VERSION ""

NS_ :

BS_:

BU_: Connectivity CCU
VAL_TABLE_ vtbSensorReqCause 15 "SNA" 2 "by Request 2" 1 "by Request 1" 0 "normal cycle" ;
VAL_TABLE_ vtbErrorDescription 255 "ERROR" ;

BO_ 1300 msg_conn_vdc: 1 Connectivity
 SG_ sig_conn_vdc : 0|8@1+ (1,0) [0|255] ""  CCU

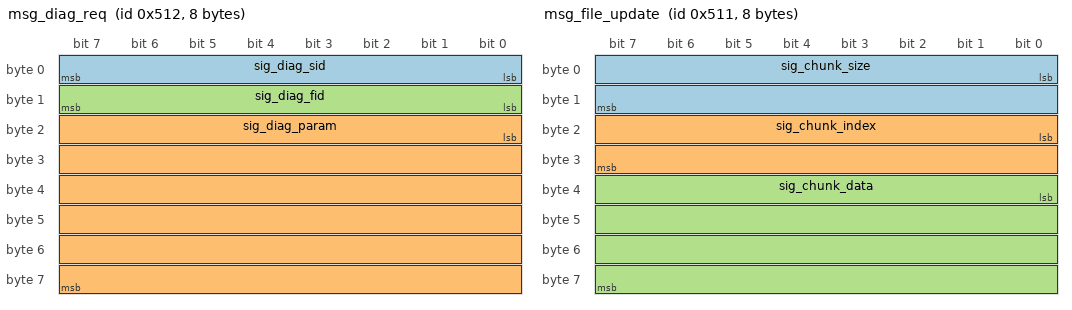
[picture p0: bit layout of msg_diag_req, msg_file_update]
BO_ 1298 msg_diag_req: 8 Connectivity
 SG_ sig_diag_sid : 0|8@1+ (1,0) [0|255] ""  CCU
 SG_ sig_diag_param : 16|48@1+ (1,0) [0|281474976710655] ""  CCU
 SG_ sig_diag_fid : 8|8@1+ (1,0) [0|255] ""  CCU

BO_ 1297 msg_file_update: 8 Connectivity
 SG_ sig_chunk_size : 0|16@1+ (1,0) [0|65535] ""  CCU
 SG_ sig_chunk_index : 16|16@1+ (1,0) [0|65535] ""  CCU
 SG_ sig_chunk_data : 32|32@1+ (1,0) [0|4294967295] ""  CCU

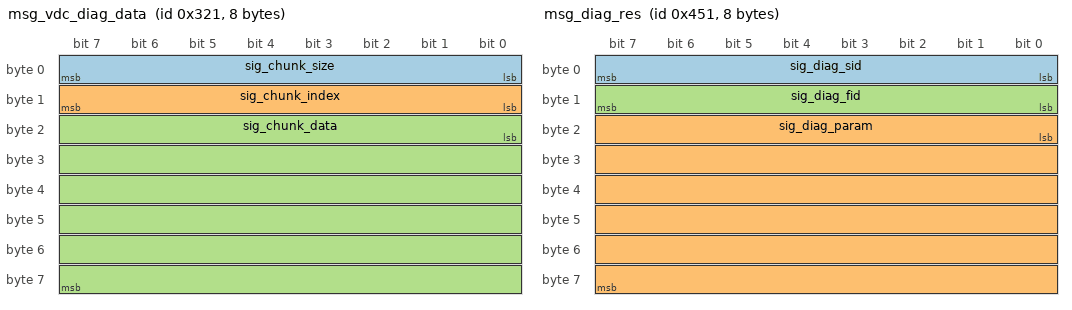
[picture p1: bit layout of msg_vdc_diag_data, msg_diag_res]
BO_ 801 msg_vdc_diag_data: 8 CCU
 SG_ sig_chunk_size : 0|8@1+ (1,0) [0|255] ""  Connectivity
 SG_ sig_chunk_index : 8|8@1+ (1,0) [0|255] ""  Connectivity
 SG_ sig_chunk_data : 16|48@1+ (1,0) [0|281474976710655] ""  Connectivity

BO_ 1105 msg_diag_res: 8 CCU
 SG_ sig_diag_sid : 0|8@1+ (1,0) [0|255] ""  Connectivity
 SG_ sig_diag_param : 16|48@1+ (1,0) [0|281474976710655] ""  Connectivity
 SG_ sig_diag_fid : 8|8@1+ (1,0) [0|255] ""  Connectivity

BA_DEF_  "DatabaseVersion" STRING ;
BA_DEF_  "Manufacturer" STRING ;
BA_DEF_ BU_  "NodeLayerModules" STRING ;
BA_DEF_  "BusType" STRING ;
BA_DEF_ SG_  "GenSigSendType" ENUM  "Cyclic","OnWrite","OnWriteWithRepetition","OnChange","OnChangeWithRepetition","IfActive","IfActiveWithRepetition","NoSigSendType","NotUsed","NotUsed","NotUsed","NotUsed","NotUsed";
BA_DEF_ BO_  "GenMsgSendType" ENUM  "Cyclic","NotUsed","NotUsed","NotUsed","NotUsed","Cyclic","NotUsed","IfActive","NoMsgSendType","NotUsed","vector_leerstring";
BA_DEF_ BO_  "GenMsgCycleTime" INT 0 50000;
BA_DEF_ BO_  "GenMsgCycleTimeFast" INT 0 50000;
BA_DEF_ BO_  "GenMsgILSupport" ENUM  "No","Yes";
BA_DEF_DEF_  "DatabaseVersion" "";
BA_DEF_DEF_  "Manufacturer" "Vector";
BA_DEF_DEF_  "NodeLayerModules" "CANoeILNLVector.dll";
BA_DEF_DEF_  "BusType" "CAN";
BA_DEF_DEF_  "GenSigSendType" "Cyclic";
BA_DEF_DEF_  "GenMsgSendType" "NoMsgSendType";
BA_DEF_DEF_  "GenMsgCycleTime" 200;
BA_DEF_DEF_  "GenMsgCycleTimeFast" 20;
BA_DEF_DEF_  "GenMsgILSupport" "Yes";
BA_ "DatabaseVersion" "1.1";
